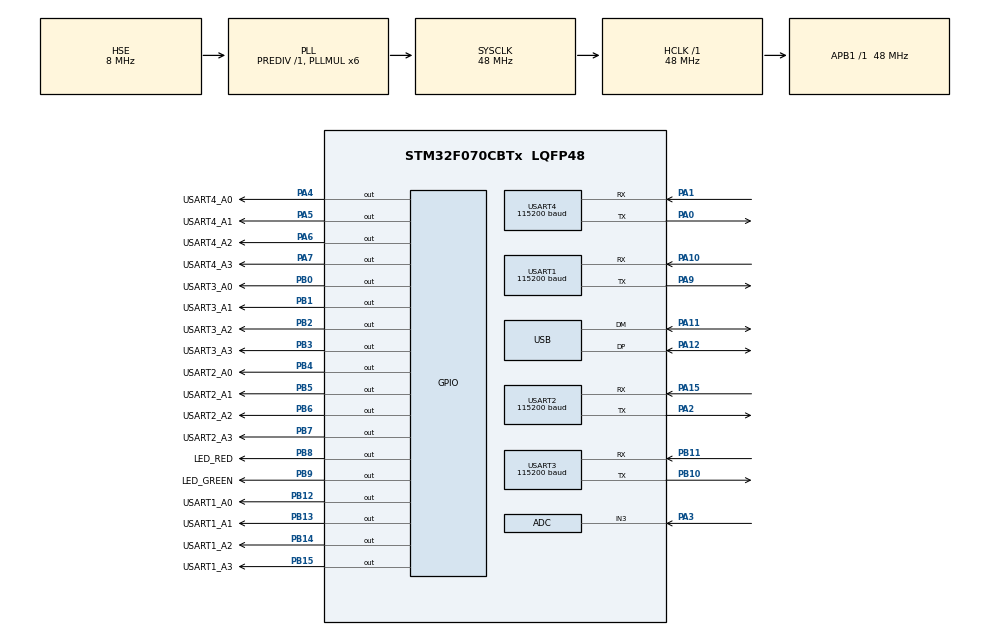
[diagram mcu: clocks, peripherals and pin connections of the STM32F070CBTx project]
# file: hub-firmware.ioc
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Mcu.Family=STM32F0
Mcu.Name=STM32F070CBTx
Mcu.Package=LQFP48
NVIC.TIM17_IRQn=true\:0\:0\:false\:false\:true\:false\:true
NVIC.TimeBase=TIM17_IRQn
NVIC.TimeBaseIP=TIM17
NVIC.USART1_IRQn=true\:0\:0\:false\:false\:true\:true\:true
NVIC.USART2_IRQn=true\:0\:0\:false\:false\:true\:true\:true
NVIC.USART3_4_IRQn=true\:0\:0\:false\:false\:true\:true\:true
NVIC.USB_IRQn=true\:0\:0\:false\:false\:true\:true\:true
PA0.Mode=Asynchronous
PA0.Signal=USART4_TX
PA1.Mode=Asynchronous
PA1.Signal=USART4_RX
PA10.Mode=Asynchronous
PA10.Signal=USART1_RX
PA11.Mode=Device
PA11.Signal=USB_DM
PA12.Mode=Device
PA12.Signal=USB_DP
PA13.GPIO_Label=SWDIO
PA13.Mode=Serial_Wire
PA13.Signal=SYS_SWDIO
PA14.GPIO_Label=SWCLK
PA14.Mode=Serial_Wire
PA14.Signal=SYS_SWCLK
PA15.Mode=Asynchronous
PA15.Signal=USART2_RX
PA2.Mode=Asynchronous
PA2.Signal=USART2_TX
PA3.Mode=IN3
PA3.Signal=ADC_IN3
PA4.GPIO_Label=USART4_A0
PA4.GPIO_Speed=GPIO_SPEED_FREQ_HIGH
PA4.Signal=GPIO_Output
PA5.GPIO_Label=USART4_A1
PA5.GPIO_Speed=GPIO_SPEED_FREQ_HIGH
PA5.Signal=GPIO_Output
PA6.GPIO_Label=USART4_A2
PA6.GPIO_Speed=GPIO_SPEED_FREQ_HIGH
PA6.Signal=GPIO_Output
PA7.GPIO_Label=USART4_A3
PA7.GPIO_Speed=GPIO_SPEED_FREQ_HIGH
PA7.Signal=GPIO_Output
PA9.Mode=Asynchronous
PA9.Signal=USART1_TX
PB0.GPIO_Label=USART3_A0
PB0.GPIO_Speed=GPIO_SPEED_FREQ_HIGH
PB0.Signal=GPIO_Output
PB1.GPIO_Label=USART3_A1
PB1.GPIO_Speed=GPIO_SPEED_FREQ_HIGH
PB1.Signal=GPIO_Output
PB10.Mode=Asynchronous
PB10.Signal=USART3_TX
PB11.Mode=Asynchronous
PB11.Signal=USART3_RX
PB12.GPIO_Label=USART1_A0
PB12.GPIO_Speed=GPIO_SPEED_FREQ_HIGH
PB12.Signal=GPIO_Output
PB13.GPIO_Label=USART1_A1
PB13.GPIO_Speed=GPIO_SPEED_FREQ_HIGH
PB13.Signal=GPIO_Output
PB14.GPIO_Label=USART1_A2
PB14.GPIO_Speed=GPIO_SPEED_FREQ_HIGH
PB14.Signal=GPIO_Output
PB15.GPIO_Label=USART1_A3
PB15.GPIO_Speed=GPIO_SPEED_FREQ_HIGH
PB15.Signal=GPIO_Output
PB2.GPIO_Label=USART3_A2
PB2.GPIO_Speed=GPIO_SPEED_FREQ_HIGH
PB2.Signal=GPIO_Output
PB3.GPIO_Label=USART3_A3
PB3.GPIO_Speed=GPIO_SPEED_FREQ_HIGH
PB3.Signal=GPIO_Output
PB4.GPIO_Label=USART2_A0
PB4.GPIO_Speed=GPIO_SPEED_FREQ_HIGH
PB4.Signal=GPIO_Output
PB5.GPIO_Label=USART2_A1
PB5.GPIO_Speed=GPIO_SPEED_FREQ_HIGH
PB5.Signal=GPIO_Output
PB6.GPIO_Label=USART2_A2
PB6.GPIO_Speed=GPIO_SPEED_FREQ_HIGH
PB6.Signal=GPIO_Output
PB7.GPIO_Label=USART2_A3
PB7.GPIO_Speed=GPIO_SPEED_FREQ_HIGH
PB7.Signal=GPIO_Output
PB8.GPIO_Label=LED_RED
PB8.PinState=GPIO_PIN_SET
PB8.Signal=GPIO_Output
PB9.GPIO_Label=LED_GREEN
PB9.PinState=GPIO_PIN_SET
PB9.Signal=GPIO_Output
PF0-OSC_IN.GPIO_Label=CLK8_IN
PF0-OSC_IN.Mode=HSE-External-Clock-Source
PF0-OSC_IN.Signal=RCC_OSC_IN
ProjectManager.HeapSize=0x200
ProjectManager.StackSize=0x400
ProjectManager.TargetToolchain=Makefile
RCC.AHBFreq_Value=48000000
RCC.APB1Freq_Value=48000000
RCC.APB1TimFreq_Value=48000000
RCC.HCLKFreq_Value=48000000
RCC.PLLMUL=RCC_PLL_MUL6
RCC.SYSCLKFreq_VALUE=48000000
RCC.SYSCLKSource=RCC_SYSCLKSOURCE_PLLCLK
USART1.BaudRate=115200
USART1.VirtualMode-Asynchronous=VM_ASYNC
USART2.BaudRate=115200
USART2.VirtualMode-Asynchronous=VM_ASYNC
USART3.BaudRate=115200
USART3.VirtualMode-Asynchronous=VM_ASYNC
USART4.BaudRate=115200
USART4.VirtualMode-Asynchronous=VM_ASYNC
USB.lpm_enable=DISABLE
USB_DEVICE.APP_RX_DATA_SIZE=128
USB_DEVICE.APP_TX_DATA_SIZE=128
USB_DEVICE.CLASS_NAME_FS=CDC
USB_DEVICE.MANUFACTURER_STRING=Epicom
USB_DEVICE.PID_CDC_FS=0x5740
USB_DEVICE.PRODUCT_STRING_CDC_FS=Blaster Test Hub
USB_DEVICE.VID=0x483
USB_DEVICE.VirtualMode=Cdc
USB_DEVICE.VirtualModeFS=Cdc_FS
VP_SYS_VS_tim17.Mode=TIM17
VP_USB_DEVICE_VS_USB_DEVICE_CDC_FS.Mode=CDC_FS
board=custom

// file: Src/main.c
/* USER CODE BEGIN Header */
/**
  ******************************************************************************
  * @file           : main.c
  * @brief          : Main program body
  ******************************************************************************
  * @attention
  *
  * <h2><center>&copy; Copyright (c) 2019 STMicroelectronics.
  * All rights reserved.</center></h2>
  *
  * This software component is licensed by ST under Ultimate Liberty license
  * SLA0044, the "License"; You may not use this file except in compliance with
  * the License. You may obtain a copy of the License at:
  *                             www.st.com/SLA0044
  *
  ******************************************************************************
  */
/* USER CODE END Header */

#include "main.h"
#include "usb_device.h"

/* USER CODE BEGIN Includes */
#include "SEGGER_RTT.h"
#include "usbd_cdc_if.h"
/* USER CODE END Includes */

ADC_HandleTypeDef hadc;

UART_HandleTypeDef huart1;
UART_HandleTypeDef huart2;
UART_HandleTypeDef huart3;
UART_HandleTypeDef huart4;

void SystemClock_Config(void);
static void MX_GPIO_Init(void);
static void MX_ADC_Init(void);
static void MX_USART1_UART_Init(void);
static void MX_USART2_UART_Init(void);
static void MX_USART3_UART_Init(void);
static void MX_USART4_UART_Init(void);

int main(void)
{

  /* MCU Configuration--------------------------------------------------------*/

  /* Reset of all peripherals, Initializes the Flash interface and the Systick. */
  HAL_Init();

  /* Configure the system clock */
  SystemClock_Config();

  /* Initialize all configured peripherals */
  MX_GPIO_Init();
  MX_ADC_Init();
  MX_USART1_UART_Init();
  MX_USART2_UART_Init();
  MX_USART3_UART_Init();
  MX_USART4_UART_Init();
  MX_USB_DEVICE_Init();
  /* USER CODE BEGIN 2 */

  SEGGER_RTT_WriteString(0, "\nboot\n");

  /* uint8_t buf[256]; */
  /* int i;   */
  /* for (i=0; i<256; i++) { */
  /*     buf[i] = i; */
  /* } */

  extern uint8_t rxbuf[FIFO_SIZE][32];
  extern uint8_t rxlen[FIFO_SIZE];

  extern volatile int fifo_used;
  int fifo_tail = 0;

  /* USER CODE END 2 */

  /* Infinite loop */
  while (1)
  {

      /* pop from fifo */
      if (fifo_used) {
          /* use outgoing data */
          /* SEGGER_RTT_Write(0, rxbuf[fifo_tail], rxlen[fifo_tail]); */
          CDC_Transmit_FS(rxbuf[fifo_tail], rxlen[fifo_tail]);
          HAL_GPIO_TogglePin(GPIOB, LED_GREEN_Pin);
          /* fifo maintenance */
          fifo_used--;
          fifo_tail++;
          if (fifo_tail == FIFO_SIZE) {
              fifo_tail = 0;
          }
      } else {
          /* fifo was empty */
      }

  }
}

void SystemClock_Config(void)
{
  RCC_OscInitTypeDef RCC_OscInitStruct = {0};
  RCC_ClkInitTypeDef RCC_ClkInitStruct = {0};
  RCC_PeriphCLKInitTypeDef PeriphClkInit = {0};

  /** Initializes the CPU, AHB and APB busses clocks
  */
  RCC_OscInitStruct.OscillatorType = RCC_OSCILLATORTYPE_HSI14|RCC_OSCILLATORTYPE_HSE;
  RCC_OscInitStruct.HSEState = RCC_HSE_BYPASS;
  RCC_OscInitStruct.HSI14State = RCC_HSI14_ON;
  RCC_OscInitStruct.HSI14CalibrationValue = 16;
  RCC_OscInitStruct.PLL.PLLState = RCC_PLL_ON;
  RCC_OscInitStruct.PLL.PLLSource = RCC_PLLSOURCE_HSE;
  RCC_OscInitStruct.PLL.PLLMUL = RCC_PLL_MUL6;
  RCC_OscInitStruct.PLL.PREDIV = RCC_PREDIV_DIV1;
  if (HAL_RCC_OscConfig(&RCC_OscInitStruct) != HAL_OK)
  {
    Error_Handler();
  }
  /** Initializes the CPU, AHB and APB busses clocks
  */
  RCC_ClkInitStruct.ClockType = RCC_CLOCKTYPE_HCLK|RCC_CLOCKTYPE_SYSCLK
                              |RCC_CLOCKTYPE_PCLK1;
  RCC_ClkInitStruct.SYSCLKSource = RCC_SYSCLKSOURCE_PLLCLK;
  RCC_ClkInitStruct.AHBCLKDivider = RCC_SYSCLK_DIV1;
  RCC_ClkInitStruct.APB1CLKDivider = RCC_HCLK_DIV1;

  if (HAL_RCC_ClockConfig(&RCC_ClkInitStruct, FLASH_LATENCY_1) != HAL_OK)
  {
    Error_Handler();
  }
  PeriphClkInit.PeriphClockSelection = RCC_PERIPHCLK_USB|RCC_PERIPHCLK_USART1;
  PeriphClkInit.Usart1ClockSelection = RCC_USART1CLKSOURCE_PCLK1;
  PeriphClkInit.UsbClockSelection = RCC_USBCLKSOURCE_PLL;

  if (HAL_RCCEx_PeriphCLKConfig(&PeriphClkInit) != HAL_OK)
  {
    Error_Handler();
  }
}

static void MX_ADC_Init(void)
{

  ADC_ChannelConfTypeDef sConfig = {0};

  /** Configure the global features of the ADC (Clock, Resolution, Data Alignment and number of conversion)
  */
  hadc.Instance = ADC1;
  hadc.Init.ClockPrescaler = ADC_CLOCK_ASYNC_DIV1;
  hadc.Init.Resolution = ADC_RESOLUTION_12B;
  hadc.Init.DataAlign = ADC_DATAALIGN_RIGHT;
  hadc.Init.ScanConvMode = ADC_SCAN_DIRECTION_FORWARD;
  hadc.Init.EOCSelection = ADC_EOC_SINGLE_CONV;
  hadc.Init.LowPowerAutoWait = DISABLE;
  hadc.Init.LowPowerAutoPowerOff = DISABLE;
  hadc.Init.ContinuousConvMode = DISABLE;
  hadc.Init.DiscontinuousConvMode = DISABLE;
  hadc.Init.ExternalTrigConv = ADC_SOFTWARE_START;
  hadc.Init.ExternalTrigConvEdge = ADC_EXTERNALTRIGCONVEDGE_NONE;
  hadc.Init.DMAContinuousRequests = DISABLE;
  hadc.Init.Overrun = ADC_OVR_DATA_PRESERVED;
  if (HAL_ADC_Init(&hadc) != HAL_OK)
  {
    Error_Handler();
  }
  /** Configure for the selected ADC regular channel to be converted.
  */
  sConfig.Channel = ADC_CHANNEL_3;
  sConfig.Rank = ADC_RANK_CHANNEL_NUMBER;
  sConfig.SamplingTime = ADC_SAMPLETIME_1CYCLE_5;
  if (HAL_ADC_ConfigChannel(&hadc, &sConfig) != HAL_OK)
  {
    Error_Handler();
  }

}

static void MX_USART1_UART_Init(void)
{

  huart1.Instance = USART1;
  huart1.Init.BaudRate = 115200;
  huart1.Init.WordLength = UART_WORDLENGTH_8B;
  huart1.Init.StopBits = UART_STOPBITS_1;
  huart1.Init.Parity = UART_PARITY_NONE;
  huart1.Init.Mode = UART_MODE_TX_RX;
  huart1.Init.HwFlowCtl = UART_HWCONTROL_NONE;
  huart1.Init.OverSampling = UART_OVERSAMPLING_16;
  huart1.Init.OneBitSampling = UART_ONE_BIT_SAMPLE_DISABLE;
  huart1.AdvancedInit.AdvFeatureInit = UART_ADVFEATURE_NO_INIT;
  if (HAL_UART_Init(&huart1) != HAL_OK)
  {
    Error_Handler();
  }

}

static void MX_USART2_UART_Init(void)
{

  huart2.Instance = USART2;
  huart2.Init.BaudRate = 115200;
  huart2.Init.WordLength = UART_WORDLENGTH_8B;
  huart2.Init.StopBits = UART_STOPBITS_1;
  huart2.Init.Parity = UART_PARITY_NONE;
  huart2.Init.Mode = UART_MODE_TX_RX;
  huart2.Init.HwFlowCtl = UART_HWCONTROL_NONE;
  huart2.Init.OverSampling = UART_OVERSAMPLING_16;
  huart2.Init.OneBitSampling = UART_ONE_BIT_SAMPLE_DISABLE;
  huart2.AdvancedInit.AdvFeatureInit = UART_ADVFEATURE_NO_INIT;
  if (HAL_UART_Init(&huart2) != HAL_OK)
  {
    Error_Handler();
  }

}

static void MX_USART3_UART_Init(void)
{

  huart3.Instance = USART3;
  huart3.Init.BaudRate = 115200;
  huart3.Init.WordLength = UART_WORDLENGTH_8B;
  huart3.Init.StopBits = UART_STOPBITS_1;
  huart3.Init.Parity = UART_PARITY_NONE;
  huart3.Init.Mode = UART_MODE_TX_RX;
  huart3.Init.HwFlowCtl = UART_HWCONTROL_NONE;
  huart3.Init.OverSampling = UART_OVERSAMPLING_16;
  huart3.Init.OneBitSampling = UART_ONE_BIT_SAMPLE_DISABLE;
  huart3.AdvancedInit.AdvFeatureInit = UART_ADVFEATURE_NO_INIT;
  if (HAL_UART_Init(&huart3) != HAL_OK)
  {
    Error_Handler();
  }

}

static void MX_USART4_UART_Init(void)
{

  huart4.Instance = USART4;
  huart4.Init.BaudRate = 115200;
  huart4.Init.WordLength = UART_WORDLENGTH_8B;
  huart4.Init.StopBits = UART_STOPBITS_1;
  huart4.Init.Parity = UART_PARITY_NONE;
  huart4.Init.Mode = UART_MODE_TX_RX;
  huart4.Init.HwFlowCtl = UART_HWCONTROL_NONE;
  huart4.Init.OverSampling = UART_OVERSAMPLING_16;
  huart4.Init.OneBitSampling = UART_ONE_BIT_SAMPLE_DISABLE;
  huart4.AdvancedInit.AdvFeatureInit = UART_ADVFEATURE_NO_INIT;
  if (HAL_UART_Init(&huart4) != HAL_OK)
  {
    Error_Handler();
  }

}

static void MX_GPIO_Init(void)
{
  GPIO_InitTypeDef GPIO_InitStruct = {0};

  /* GPIO Ports Clock Enable */
  __HAL_RCC_GPIOF_CLK_ENABLE();
  __HAL_RCC_GPIOA_CLK_ENABLE();
  __HAL_RCC_GPIOB_CLK_ENABLE();

  /*Configure GPIO pin Output Level */
  HAL_GPIO_WritePin(GPIOA, USART4_A0_Pin|USART4_A1_Pin|USART4_A2_Pin|USART4_A3_Pin, GPIO_PIN_RESET);

  /*Configure GPIO pin Output Level */
  HAL_GPIO_WritePin(GPIOB, USART3_A0_Pin|USART3_A1_Pin|USART3_A2_Pin|USART1_A0_Pin
                          |USART1_A1_Pin|USART1_A2_Pin|USART1_A3_Pin|USART3_A3_Pin
                          |USART2_A0_Pin|USART2_A1_Pin|USART2_A2_Pin|USART2_A3_Pin, GPIO_PIN_RESET);

  /*Configure GPIO pin Output Level */
  HAL_GPIO_WritePin(GPIOB, LED_RED_Pin|LED_GREEN_Pin, GPIO_PIN_SET);

  /*Configure GPIO pins : USART4_A0_Pin USART4_A1_Pin USART4_A2_Pin USART4_A3_Pin */
  GPIO_InitStruct.Pin = USART4_A0_Pin|USART4_A1_Pin|USART4_A2_Pin|USART4_A3_Pin;
  GPIO_InitStruct.Mode = GPIO_MODE_OUTPUT_PP;
  GPIO_InitStruct.Pull = GPIO_NOPULL;
  GPIO_InitStruct.Speed = GPIO_SPEED_FREQ_HIGH;
  HAL_GPIO_Init(GPIOA, &GPIO_InitStruct);

  /*Configure GPIO pins : USART3_A0_Pin USART3_A1_Pin USART3_A2_Pin USART1_A0_Pin
                           USART1_A1_Pin USART1_A2_Pin USART1_A3_Pin USART3_A3_Pin
                           USART2_A0_Pin USART2_A1_Pin USART2_A2_Pin USART2_A3_Pin */
  GPIO_InitStruct.Pin = USART3_A0_Pin|USART3_A1_Pin|USART3_A2_Pin|USART1_A0_Pin
                          |USART1_A1_Pin|USART1_A2_Pin|USART1_A3_Pin|USART3_A3_Pin
                          |USART2_A0_Pin|USART2_A1_Pin|USART2_A2_Pin|USART2_A3_Pin;
  GPIO_InitStruct.Mode = GPIO_MODE_OUTPUT_PP;
  GPIO_InitStruct.Pull = GPIO_NOPULL;
  GPIO_InitStruct.Speed = GPIO_SPEED_FREQ_HIGH;
  HAL_GPIO_Init(GPIOB, &GPIO_InitStruct);

  /*Configure GPIO pins : LED_RED_Pin LED_GREEN_Pin */
  GPIO_InitStruct.Pin = LED_RED_Pin|LED_GREEN_Pin;
  GPIO_InitStruct.Mode = GPIO_MODE_OUTPUT_PP;
  GPIO_InitStruct.Pull = GPIO_NOPULL;
  GPIO_InitStruct.Speed = GPIO_SPEED_FREQ_LOW;
  HAL_GPIO_Init(GPIOB, &GPIO_InitStruct);

}

void HAL_TIM_PeriodElapsedCallback(TIM_HandleTypeDef *htim)
{
  if (htim->Instance == TIM17) {
    HAL_IncTick();
  }
}

void Error_Handler(void)
{
}

/************************ (C) COPYRIGHT STMicroelectronics *****END OF FILE****/
